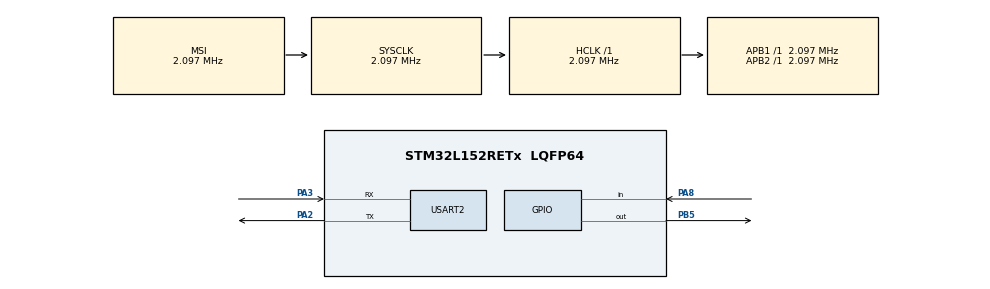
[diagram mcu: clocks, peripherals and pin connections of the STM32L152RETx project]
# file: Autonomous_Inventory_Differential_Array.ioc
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Mcu.Family=STM32L1
Mcu.Name=STM32L152RETx
Mcu.Package=LQFP64
NVIC.PriorityGroup=NVIC_PRIORITYGROUP_4
PA2.Mode=Asynchronous
PA2.Signal=USART2_TX
PA3.Mode=Asynchronous
PA3.Signal=USART2_RX
PA8.Signal=GPIO_Input
PB5.Signal=GPIO_Output
ProjectManager.HeapSize=0x200
ProjectManager.StackSize=0x400
ProjectManager.TargetToolchain=STM32CubeIDE
RCC.AHBFreq_Value=2097000
RCC.APB1Freq_Value=2097000
RCC.APB2Freq_Value=2097000
RCC.HSE_VALUE=24000000
RCC.HSI_VALUE=16000000
RCC.LSE_VALUE=32768
RCC.MSI_VALUE=2097000
RCC.SYSCLKFreq_VALUE=2097000
RCC.VCOOutputFreq_Value=48000000
TIM2.Prescaler=7
USART2.VirtualMode=VM_ASYNC
VP_TIM2_VS_ClockSourceINT.Mode=Internal
board=custom

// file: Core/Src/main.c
/* USER CODE BEGIN Header */
/**
  ******************************************************************************
  * @file           : main.c
  * @brief          : Main program body
  ******************************************************************************
  * @attention
  *
  * Copyright (c) 2024 STMicroelectronics.
  * All rights reserved.
  *
  * This software is licensed under terms that can be found in the LICENSE file
  * in the root directory of this software component.
  * If no LICENSE file comes with this software, it is provided AS-IS.
  *
  ******************************************************************************
  */
/* USER CODE END Header */
#include "main.h"
#include "tim.h"
#include "usart.h"
#include "gpio.h"

/* USER CODE BEGIN Includes */
#include "stdio.h"
#include "stdbool.h"
#include <function_calibration.h>
#include <function_main.h>
#include <manager_mux.h>
#include <manager_weight.h>
/* USER CODE END Includes */

void SystemClock_Config(void);

/* USER CODE BEGIN 0 */

// change these GPIO to the peripherals and pins we are using for project
#define DT_PIN GPIO_PIN_8
#define DT_PORT GPIOA
#define SCK_PIN GPIO_PIN_5
#define SCK_PORT GPIOB

/* USER CODE END 0 */

int main(void)
{

  /* MCU Configuration--------------------------------------------------------*/

  /* Reset of all peripherals, Initializes the Flash interface and the Systick. */
  HAL_Init();

  /* Configure the system clock */
  SystemClock_Config();

  /* Initialize all configured peripherals */
  MX_GPIO_Init();
  MX_TIM2_Init();
  MX_USART2_UART_Init();

  /* Infinite loop */
  /* USER CODE BEGIN WHILE */

  Calibrate();
  main_function();

    /* USER CODE END WHILE */

}

void SystemClock_Config(void)
{
  RCC_OscInitTypeDef RCC_OscInitStruct = {0};
  RCC_ClkInitTypeDef RCC_ClkInitStruct = {0};

  /** Configure the main internal regulator output voltage
  */
  __HAL_PWR_VOLTAGESCALING_CONFIG(PWR_REGULATOR_VOLTAGE_SCALE1);

  /** Initializes the RCC Oscillators according to the specified parameters
  * in the RCC_OscInitTypeDef structure.
  */
  RCC_OscInitStruct.OscillatorType = RCC_OSCILLATORTYPE_MSI;
  RCC_OscInitStruct.MSIState = RCC_MSI_ON;
  RCC_OscInitStruct.MSICalibrationValue = 0;
  RCC_OscInitStruct.MSIClockRange = RCC_MSIRANGE_5;
  RCC_OscInitStruct.PLL.PLLState = RCC_PLL_NONE;
  if (HAL_RCC_OscConfig(&RCC_OscInitStruct) != HAL_OK)
  {
    Error_Handler();
  }

  /** Initializes the CPU, AHB and APB buses clocks
  */
  RCC_ClkInitStruct.ClockType = RCC_CLOCKTYPE_HCLK|RCC_CLOCKTYPE_SYSCLK
                              |RCC_CLOCKTYPE_PCLK1|RCC_CLOCKTYPE_PCLK2;
  RCC_ClkInitStruct.SYSCLKSource = RCC_SYSCLKSOURCE_MSI;
  RCC_ClkInitStruct.AHBCLKDivider = RCC_SYSCLK_DIV1;
  RCC_ClkInitStruct.APB1CLKDivider = RCC_HCLK_DIV1;
  RCC_ClkInitStruct.APB2CLKDivider = RCC_HCLK_DIV1;

  if (HAL_RCC_ClockConfig(&RCC_ClkInitStruct, FLASH_LATENCY_0) != HAL_OK)
  {
    Error_Handler();
  }
}

void Error_Handler(void)
{
  __disable_irq();
  while (1)
  {
  }
}
